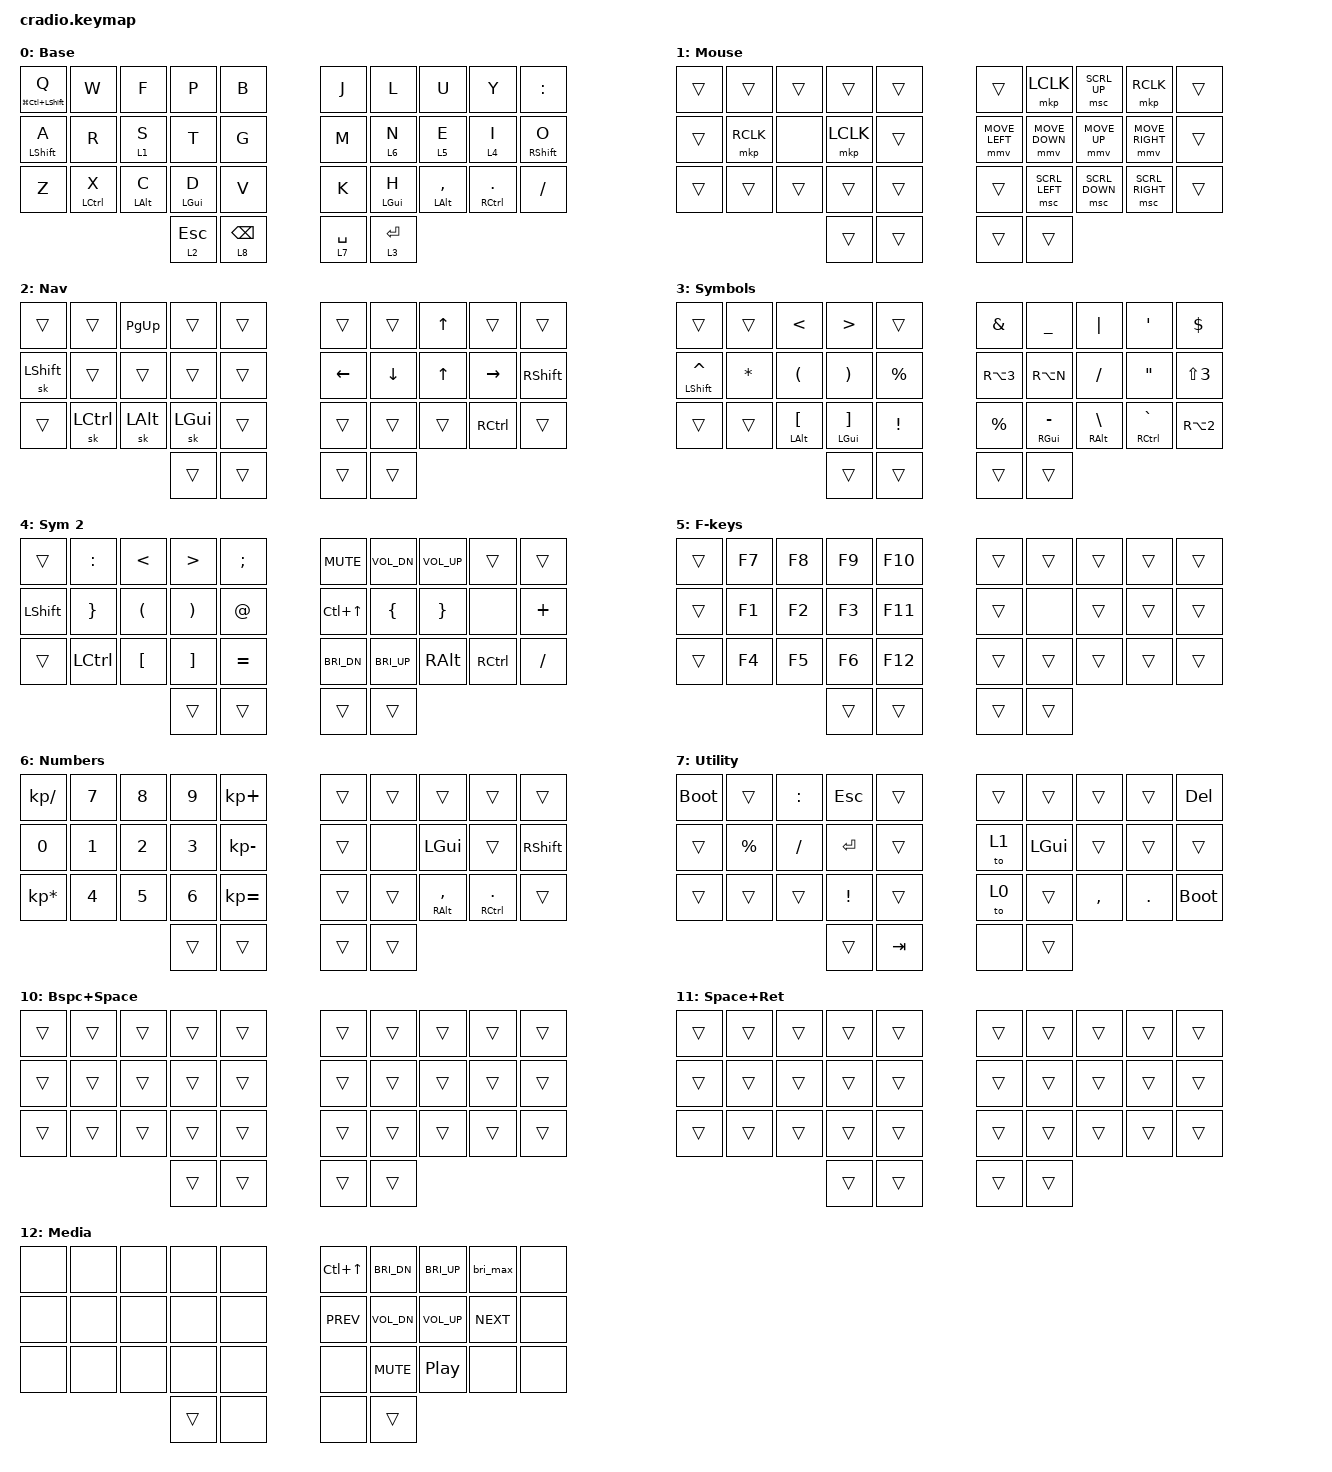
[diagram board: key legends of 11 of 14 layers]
// Copyright (c) 2022 The ZMK Contributors
// SPDX-License-Identifier: MIT

#include <behaviors.dtsi>
#include <dt-bindings/zmk/keys.h>
#include <dt-bindings/zmk/bt.h>
#include <dt-bindings/zmk/pointing.h>

// Indexes of the last layers below.
#define MEDIA 12
#define CLEANSHOT 13

// Tap a layer-tap key, then press and hold it within 175ms, and it repeats
// (eeee, or Backspace) instead of switching layer. Same window as mt.
&lt {
    quick-tap-ms = <175>;
};

/ {
    behaviors {
        // Balanced: a mod-tap becomes its modifier once another key goes down
        // and back up while it's held, however quick. Pressed alone it waits
        // 200ms, well above the slowest a/o taps hrm-tune measured (~140ms).
        // Keep a/o down until the capital letter is back up.
        mt: mod_tap {
            compatible = "zmk,behavior-hold-tap";
            label = "MOD_TAP";
            #binding-cells = <2>;
            flavor = "balanced";
            tapping-term-ms = <200>;
            quick-tap-ms = <175>;
            require-prior-idle-ms = <0>;
            bindings = <&kp>, <&kp>;
        };

    };

    macros {
        // Brightness up 20 times. The HID "brightness max" key (C_BRI_MAX)
        // is ignored by macOS; 20 steps tops out on macOS (16) and on Linux
        // (5% steps). Used on the Media layer.
        bri_max: brightness_max {
            compatible = "zmk,behavior-macro";
            display-name = "Bright max";
            #binding-cells = <0>;
            wait-ms = <10>;
            tap-ms = <10>;
            bindings = <&macro_tap
                &kp C_BRI_UP &kp C_BRI_UP &kp C_BRI_UP &kp C_BRI_UP &kp C_BRI_UP
                &kp C_BRI_UP &kp C_BRI_UP &kp C_BRI_UP &kp C_BRI_UP &kp C_BRI_UP
                &kp C_BRI_UP &kp C_BRI_UP &kp C_BRI_UP &kp C_BRI_UP &kp C_BRI_UP
                &kp C_BRI_UP &kp C_BRI_UP &kp C_BRI_UP &kp C_BRI_UP &kp C_BRI_UP>;
        };
    };

    conditional_layers {
        compatible = "zmk,conditional-layers";
        bspc_ret {
            if-layers = <8 3>;
            then-layer = <9>;
        };
        bspc_space {
            if-layers = <8 7>;
            then-layer = <10>;
        };
        space_ret {
            if-layers = <7 3>;
            then-layer = <11>;
        };
        esc_space {
            if-layers = <2 7>;
            then-layer = <CLEANSHOT>;
        };
        esc_ret {
            if-layers = <2 3>;
            then-layer = <MEDIA>;
        };
    };

    keymap {
        compatible = "zmk,keymap";

        // Layer 0: Default (Base Colemak-DH)
        default_layer {
            display-name = "Base";
            bindings = <
        //╭──────────┬──────────┬──────────┬──────────┬──────────╮   ╭──────────┬──────────┬──────────┬──────────┬──────────╮
        //│GUI+CTL+  │  W       │  F       │  P       │  B       │   │  J       │  L       │  U       │  Y       │  :       │
        //│  SFT+Q   │          │          │          │          │   │          │          │          │          │          │
            &mt LG(LC(LSHFT)) Q &kp W &kp F &kp P &kp B            &kp J &kp L &kp U &kp Y &kp COLON
        //├──────────┼──────────┼──────────┼──────────┼──────────┤   ├──────────┼──────────┼──────────┼──────────┼──────────┤
        //│ LSFT+A   │  R       │ LT1+S    │  T       │  G       │   │  M       │ LT6+N    │ LT5+E    │ LT4+I    │ RSFT+O   │
            &mt LSHFT A &kp R    &lt 1 S    &kp T      &kp G          &kp M      &lt 6 N    &lt 5 E    &lt 4 I    &mt RSHFT O
        //├──────────┼──────────┼──────────┼──────────┼──────────┤   ├──────────┼──────────┼──────────┼──────────┼──────────┤
        //│  Z       │ LCTL+X   │ LALT+C   │ LGUI+D   │  V       │   │  K       │ LGUI+H   │ LALT+,   │ RCTL+.   │  /       │
            &kp Z      &mt LCTRL X &mt LALT C &mt LGUI D &kp V       &kp K      &mt LGUI H &mt LALT COMMA &mt RCTRL DOT &kp FSLH
        //╰──────────┴──────────┴──────────┼──────────┼──────────┤   ├──────────┼──────────┼──────────┴──────────┴──────────╯
                                            &lt 2 ESC   &lt 8 BSPC    &lt 7 SPACE &lt 3 RET
        //                                 ╰──────────┴──────────╯   ╰──────────┴──────────╯
            >;
        };

        // Layer 1: Mouse controls (accessed via S key)
        layer_1 {
            display-name = "Mouse";
            bindings = <
        //╭──────────┬──────────┬──────────┬──────────┬──────────╮   ╭──────────┬──────────┬──────────┬──────────┬──────────╮
        //│          │          │          │          │          │   │          │ LCLK     │ SCR_UP   │ RCLK     │          │
            &trans     &trans     &trans     &trans     &trans         &trans     &mkp LCLK  &msc SCRL_UP &mkp RCLK &trans
        //├──────────┼──────────┼──────────┼──────────┼──────────┤   ├──────────┼──────────┼──────────┼──────────┼──────────┤
        //│          │ RCLK     │          │ LCLK     │          │   │ M_LEFT   │ M_DOWN   │ M_UP     │ M_RIGHT  │          │
            &trans     &mkp RCLK  &none      &mkp LCLK  &trans         &mmv MOVE_LEFT &mmv MOVE_DOWN &mmv MOVE_UP &mmv MOVE_RIGHT &trans
        //├──────────┼──────────┼──────────┼──────────┼──────────┤   ├──────────┼──────────┼──────────┼──────────┼──────────┤
        //│          │          │          │          │          │   │          │ SCR_LEFT │ SCR_DOWN │ SCR_RIGHT│          │
            &trans     &trans     &trans     &trans     &trans         &trans     &msc SCRL_LEFT &msc SCRL_DOWN &msc SCRL_RIGHT &trans
        //╰──────────┴──────────┴──────────┼──────────┼──────────┤   ├──────────┼──────────┼──────────┴──────────┴──────────╯
                                             &trans     &trans         &trans     &trans
        //                                 ╰──────────┴──────────╯   ╰──────────┴──────────╯
            >;
        };

        // Layer 2: Navigation and One-shot modifiers (accessed via ESC key)
        layer_2 {
            display-name = "Nav";
            bindings = <
        //╭──────────┬──────────┬──────────┬──────────┬──────────╮   ╭──────────┬──────────┬──────────┬──────────┬──────────╮
        //│          │          │ PAGE_UP  │          │          │   │          │          │ UP       │          │          │
            &trans     &trans     &kp PG_UP  &trans     &trans         &trans     &trans     &kp UP     &trans     &trans
        //├──────────┼──────────┼──────────┼──────────┼──────────┤   ├──────────┼──────────┼──────────┼──────────┼──────────┤
        //│ OS_LSFT  │          │          │          │          │   │ LEFT     │ DOWN     │ UP       │ RIGHT    │ RSFT     │
            &sk LSHFT  &trans     &trans     &trans     &trans         &kp LEFT   &kp DOWN   &kp UP     &kp RIGHT  &kp RSHFT
        //├──────────┼──────────┼──────────┼──────────┼──────────┤   ├──────────┼──────────┼──────────┼──────────┼──────────┤
        //│          │ OS_LCTL  │ OS_LALT  │ OS_LGUI  │          │   │          │          │          │ RCTL     │          │
            &trans     &sk LCTRL  &sk LALT   &sk LGUI   &trans         &trans     &trans     &trans     &kp RCTRL  &trans
        //╰──────────┴──────────┴──────────┼──────────┼──────────┤   ├──────────┼──────────┼──────────┴──────────┴──────────╯
                                             &trans     &trans         &trans     &trans
        //                                 ╰──────────┴──────────╯   ╰──────────┴──────────╯
            >;
        };

        // Layer 3: Symbols (accessed via RET key)
        layer_3 {
            display-name = "Symbols";
            bindings = <
        //╭──────────┬──────────┬──────────┬──────────┬──────────╮   ╭──────────┬──────────┬──────────┬──────────┬──────────╮
        //│          │          │ <        │ >        │          │   │ &        │ _        │ |        │ '        │ $        │
            &trans     &trans     &kp LT     &kp GT     &trans         &kp AMPS   &kp UNDER  &kp PIPE   &kp SQT    &kp DLLR
        //├──────────┼──────────┼──────────┼──────────┼──────────┤   ├──────────┼──────────┼──────────┼──────────┼──────────┤
        //│ LSFT+^   │ *        │ (        │ )        │ %        │   │ £        │ RALT+N   │ /        │ "        │ #        │
            &mt LSHFT CARET &kp ASTRK &kp LPAR &kp RPAR &kp PRCNT     &kp RA(N3) &kp RA(N)  &kp FSLH   &kp DQT    &kp LS(N3)
        //├──────────┼──────────┼──────────┼──────────┼──────────┤   ├──────────┼──────────┼──────────┼──────────┼──────────┤
        //│          │          │ LALT+[   │ LGUI+]   │ !        │   │ %        │ RGUI+-   │ RALT+\   │ RCTL+`   │ @        │
            &trans     &trans     &mt LALT LBKT &mt LGUI RBKT &kp EXCL  &kp PRCNT &mt RGUI MINUS &mt RALT BSLH &mt RCTRL GRAVE &kp RA(N2)
        //╰──────────┴──────────┴──────────┼──────────┼──────────┤   ├──────────┼──────────┼──────────┴──────────┴──────────╯
                                             &trans     &trans         &trans     &trans
        //                                 ╰──────────┴──────────╯   ╰──────────┴──────────╯
            >;
        };

        // Layer 4: More symbols and media (accessed via I key)
        layer_4 {
            display-name = "Sym 2";
            bindings = <
        //╭──────────┬──────────┬──────────┬──────────┬──────────╮   ╭──────────┬──────────┬──────────┬──────────┬──────────╮
        //│          │ :        │ <        │ >        │ ;        │   │ MUTE     │ VOL_DN   │ VOL_UP   │          │          │
            &trans     &kp COLON  &kp LT     &kp GT     &kp SEMI       &kp C_MUTE &kp C_VOL_DN &kp C_VOL_UP &trans   &trans
        //├──────────┼──────────┼──────────┼──────────┼──────────┤   ├──────────┼──────────┼──────────┼──────────┼──────────┤
        //│ LSHIFT   │ }        │ (        │ )        │ @        │   │ RCTL_UP  │ {        │ }        │          │ +        │
            &kp LSHFT  &kp RBRC   &kp LPAR   &kp RPAR   &kp AT         &kp LC(UP) &kp LBRC   &kp RBRC   &none      &kp PLUS
        //├──────────┼──────────┼──────────┼──────────┼──────────┤   ├──────────┼──────────┼──────────┼──────────┼──────────┤
        //│          │ LCTL     │ [        │ ]        │ =        │   │ BRI_DN   │ BRI_UP   │ RALT     │ RCTL     │ /        │
            &trans     &kp LCTRL  &kp LBKT   &kp RBKT   &kp EQUAL      &kp C_BRI_DN &kp C_BRI_UP &kp RALT &kp RCTRL &kp FSLH
        //╰──────────┴──────────┴──────────┼──────────┼──────────┤   ├──────────┼──────────┼──────────┴──────────┴──────────╯
                                             &trans     &trans         &trans     &trans
        //                                 ╰──────────┴──────────╯   ╰──────────┴──────────╯
            >;
        };

        // Layer 5: Function keys (accessed via E key)
        layer_5 {
            display-name = "F-keys";
            bindings = <
        //╭──────────┬──────────┬──────────┬──────────┬──────────╮   ╭──────────┬──────────┬──────────┬──────────┬──────────╮
        //│          │ F7       │ F8       │ F9       │ F10      │   │          │          │          │          │          │
            &trans     &kp F7     &kp F8     &kp F9     &kp F10        &trans     &trans     &trans     &trans     &trans
        //├──────────┼──────────┼──────────┼──────────┼──────────┤   ├──────────┼──────────┼──────────┼──────────┼──────────┤
        //│          │ F1       │ F2       │ F3       │ F11      │   │          │          │          │          │          │
            &trans     &kp F1     &kp F2     &kp F3     &kp F11        &trans     &none      &trans     &trans     &trans
        //├──────────┼──────────┼──────────┼──────────┼──────────┤   ├──────────┼──────────┼──────────┼──────────┼──────────┤
        //│          │ F4       │ F5       │ F6       │ F12      │   │          │          │          │          │          │
            &trans     &kp F4     &kp F5     &kp F6     &kp F12        &trans     &trans     &trans     &trans     &trans
        //╰──────────┴──────────┴──────────┼──────────┼──────────┤   ├──────────┼──────────┼──────────┴──────────┴──────────╯
                                             &trans     &trans         &trans     &trans
        //                                 ╰──────────┴──────────╯   ╰──────────┴──────────╯
            >;
        };

        // Layer 6: Number pad (accessed via N key)
        layer_6 {
            display-name = "Numbers";
            bindings = <
        //╭──────────┬──────────┬──────────┬──────────┬──────────╮   ╭──────────┬──────────┬──────────┬──────────┬──────────╮
        //│ /        │ 7        │ 8        │ 9        │ +        │   │          │          │          │          │          │
            &kp KP_SLASH &kp N7   &kp N8     &kp N9     &kp KP_PLUS    &trans     &trans     &trans     &trans     &trans
        //├──────────┼──────────┼──────────┼──────────┼──────────┤   ├──────────┼──────────┼──────────┼──────────┼──────────┤
        //│ 0        │ 1        │ 2        │ 3        │ -        │   │          │          │ LGUI     │          │ RSHIFT   │
            &kp N0     &kp N1     &kp N2     &kp N3     &kp KP_MINUS   &trans     &none      &kp LGUI   &trans     &kp RSHFT
        //├──────────┼──────────┼──────────┼──────────┼──────────┤   ├──────────┼──────────┼──────────┼──────────┼──────────┤
        //│ *        │ 4        │ 5        │ 6        │ =        │   │          │          │ RALT+,   │ RCTL+.   │          │
            &kp KP_MULTIPLY &kp N4 &kp N5    &kp N6      &kp KP_EQUAL  &trans     &trans     &mt RALT COMMA &mt RCTRL DOT &trans
        //╰──────────┴──────────┴──────────┼──────────┼──────────┤   ├──────────┼──────────┼──────────┴──────────┴──────────╯
                                             &trans     &trans         &trans     &trans
        //                                 ╰──────────┴──────────╯   ╰──────────┴──────────╯
            >;
        };

        // Layer 7: Utility (accessed via SPACE key)
        layer_7 {
            display-name = "Utility";
            bindings = <
        //╭──────────┬──────────┬──────────┬──────────┬──────────╮   ╭──────────┬──────────┬──────────┬──────────┬──────────╮
        //│BOOTLOADER│          │ :        │ ESC      │          │   │          │          │          │          │ DEL      │
            &bootloader &trans    &kp COLON  &kp ESC    &trans         &trans     &trans     &trans     &trans     &kp DEL
        //├──────────┼──────────┼──────────┼──────────┼──────────┤   ├──────────┼──────────┼──────────┼──────────┼──────────┤
        //│          │ %        │ /        │ ENTER    │          │   │ TO(1)    │ LGUI     │          │          │          │
            &trans     &kp PRCNT  &kp FSLH   &kp RET    &trans         &to 1      &kp LGUI   &trans     &trans     &trans
        //├──────────┼──────────┼──────────┼──────────┼──────────┤   ├──────────┼──────────┼──────────┼──────────┼──────────┤
        //│          │          │          │ !        │          │   │ TO(0)    │          │ ,        │ .        │BOOTLOADER│
            &trans     &trans     &trans     &kp EXCL   &trans         &to 0      &trans     &kp COMMA  &kp DOT    &bootloader
        //╰──────────┴──────────┴──────────┼──────────┼──────────┤   ├──────────┼──────────┼──────────┴──────────┴──────────╯
                                             &trans     &kp TAB        &none      &trans
        //                                 ╰──────────┴──────────╯   ╰──────────┴──────────╯
            >;
        };

        // Layer 8: MEH combinations (accessed via BSPC key)
        layer_8 {
            display-name = "MEH";
            bindings = <
        //╭──────────┬──────────┬──────────┬──────────┬──────────╮   ╭──────────┬──────────┬──────────┬──────────┬──────────╮
        //│MEH+Q     │MEH+W     │MEH+F     │MEH+P     │MEH+B     │   │S-G+[     │MEH+L     │MEH+U     │S-G+]     │MEH+;     │
            &kp LC(LA(LS(Q))) &kp LC(LA(LS(W))) &kp LC(LA(LS(F))) &kp LC(LA(LS(P))) &kp LC(LA(LS(B)))   &kp LS(LG(LBKT)) &kp LC(LA(LS(L))) &kp LC(LA(LS(U))) &kp LS(LG(RBKT)) &kp LC(LA(LS(SEMI)))
        //├──────────┼──────────┼──────────┼──────────┼──────────┤   ├──────────┼──────────┼──────────┼──────────┼──────────┤
        //│MEH+A     │MEH+1     │MEH+2     │MEH+3     │MEH+G     │   │MEH+M     │MEH+N     │MEH+E     │MEH+I     │MEH+O     │
            &kp LC(LA(LS(A))) &kp LC(LA(LS(N1))) &kp LC(LA(LS(N2))) &kp LC(LA(LS(N3))) &kp LC(LA(LS(G)))   &kp LC(LA(LS(M))) &kp LC(LA(LS(N))) &kp LC(LA(LS(E))) &kp LC(LA(LS(I))) &kp LC(LA(LS(O)))
        //├──────────┼──────────┼──────────┼──────────┼──────────┤   ├──────────┼──────────┼──────────┼──────────┼──────────┤
        //│MEH+Z     │MEH+4     │MEH+5     │MEH+6     │MEH+V     │   │MEH+K     │MEH+H     │MEH+,     │MEH+.     │MEH+/     │
            &kp LC(LA(LS(Z))) &kp LC(LA(LS(N4))) &kp LC(LA(LS(N5))) &kp LC(LA(LS(N6)))      &kp LC(LA(LS(V)))   &kp LC(LA(LS(K))) &kp LC(LA(LS(H))) &kp LC(LA(LS(COMMA))) &kp LC(LA(LS(DOT))) &kp LC(LA(LS(FSLH)))
        //╰──────────┴──────────┴──────────┼──────────┼──────────┤   ├──────────┼──────────┼──────────┴──────────┴──────────╯
                                             &trans     &none          &kp LC(LA(LS(SPACE))) &trans
        //                                 ╰──────────┴──────────╯   ╰──────────┴──────────╯
            >;
        };

        // Layer 9: HYPER combinations (hold BSPC + RET, either one first)
        // Same positions as the MEH layer plus GUI: BSPC+T goes to workspace 3,
        // BSPC+RET+T takes the window there. Other keys fall through to MEH.
        // One thumb per hand; the right thumb is on RET, so HYPER+V stands in
        // for HYPER+SPACE (both move the window to the other monitor).
        // BSPC+MNEI focuses a window, BSPC+RET+MNEI moves it that way.
        // BSPC+J/Y switch tabs in an app, BSPC+RET+J/Y the windows in a group.
        // F and L take Omarchy's SUPER+F (full screen) and SUPER+L (layout),
        // which give way to ⌘F and ⌘L in apps.
        layer_9 {
            display-name = "HYPER";
            bindings = <
        //╭──────────┬──────────┬──────────┬──────────┬──────────╮   ╭──────────┬──────────┬──────────┬──────────┬──────────╮
        //│          │          │HYPER+F   │HYPER+P   │HYPER+B   │   │HYPER+J   │HYPER+L   │HYPER+U   │HYPER+Y   │          │
            &trans     &trans     &kp LG(LC(LA(LS(F)))) &kp LG(LC(LA(LS(P)))) &kp LG(LC(LA(LS(B))))   &kp LG(LC(LA(LS(J)))) &kp LG(LC(LA(LS(L)))) &kp LG(LC(LA(LS(U)))) &kp LG(LC(LA(LS(Y)))) &trans
        //├──────────┼──────────┼──────────┼──────────┼──────────┤   ├──────────┼──────────┼──────────┼──────────┼──────────┤
        //│          │HYPER+1   │HYPER+2   │HYPER+3   │          │   │HYPER+M   │HYPER+N   │HYPER+E   │HYPER+I   │          │
            &trans     &kp LG(LC(LA(LS(N1)))) &kp LG(LC(LA(LS(N2)))) &kp LG(LC(LA(LS(N3)))) &trans   &kp LG(LC(LA(LS(M)))) &kp LG(LC(LA(LS(N)))) &kp LG(LC(LA(LS(E)))) &kp LG(LC(LA(LS(I)))) &trans
        //├──────────┼──────────┼──────────┼──────────┼──────────┤   ├──────────┼──────────┼──────────┼──────────┼──────────┤
        //│          │HYPER+4   │HYPER+5   │HYPER+6   │HYPER+V   │   │          │          │          │          │          │
            &trans     &kp LG(LC(LA(LS(N4)))) &kp LG(LC(LA(LS(N5)))) &kp LG(LC(LA(LS(N6)))) &kp LG(LC(LA(LS(V))))   &trans     &trans     &trans     &trans     &trans
        //╰──────────┴──────────┴──────────┼──────────┼──────────┤   ├──────────┼──────────┼──────────┴──────────┴──────────╯
                                             &trans     &trans         &trans     &trans
        //                                 ╰──────────┴──────────╯   ╰──────────┴──────────╯
            >;
        };

        // Layer 10: Conditional BSPC + SPACE (layers 8 + 7)
        layer_10 {
            display-name = "Bspc+Space";
            bindings = <
        //╭──────────┬──────────┬──────────┬──────────┬──────────╮   ╭──────────┬──────────┬──────────┬──────────┬──────────╮
            &trans     &trans     &trans     &trans     &trans         &trans     &trans     &trans     &trans     &trans
        //├──────────┼──────────┼──────────┼──────────┼──────────┤   ├──────────┼──────────┼──────────┼──────────┼──────────┤
            &trans     &trans     &trans     &trans     &trans         &trans     &trans     &trans     &trans     &trans
        //├──────────┼──────────┼──────────┼──────────┼──────────┤   ├──────────┼──────────┼──────────┼──────────┼──────────┤
            &trans     &trans     &trans     &trans     &trans         &trans     &trans     &trans     &trans     &trans
        //╰──────────┴──────────┴──────────┼──────────┼──────────┤   ├──────────┼──────────┼──────────┴──────────┴──────────╯
                                             &trans     &trans         &trans     &trans
        //                                 ╰──────────┴──────────╯   ╰──────────┴──────────╯
            >;
        };

        // Layer 11: Conditional SPACE + ENTER (layers 7 + 3)
        layer_11 {
            display-name = "Space+Ret";
            bindings = <
        //╭──────────┬──────────┬──────────┬──────────┬──────────╮   ╭──────────┬──────────┬──────────┬──────────┬──────────╮
            &trans     &trans     &trans     &trans     &trans         &trans     &trans     &trans     &trans     &trans
        //├──────────┼──────────┼──────────┼──────────┼──────────┤   ├──────────┼──────────┼──────────┼──────────┼──────────┤
            &trans     &trans     &trans     &trans     &trans         &trans     &trans     &trans     &trans     &trans
        //├──────────┼──────────┼──────────┼──────────┼──────────┤   ├──────────┼──────────┼──────────┼──────────┼──────────┤
            &trans     &trans     &trans     &trans     &trans         &trans     &trans     &trans     &trans     &trans
        //╰──────────┴──────────┴──────────┼──────────┼──────────┤   ├──────────┼──────────┼──────────┴──────────┴──────────╯
                                             &trans     &trans         &trans     &trans
        //                                 ╰──────────┴──────────╯   ╰──────────┴──────────╯
            >;
        };

        // Layer 12: Media (hold ESC + RET, either one first)
        // A Mac's top row. M N E I are left/down/up/right as everywhere else:
        // previous track, volume down, volume up, next track. Brightness sits
        // above the volume keys (Y: all the way up), mute and play/pause below
        // them, and J is Mission Control. Everything else is blocked, so
        // nothing falls through to the Nav or Symbols layer the thumbs hold.
        media_layer {
            display-name = "Media";
            bindings = <
        //╭──────────┬──────────┬──────────┬──────────┬──────────╮   ╭──────────┬──────────┬──────────┬──────────┬──────────╮
        //│          │          │          │          │          │   │ MISSION  │ BRI_DN   │ BRI_UP   │ BRI_MAX  │          │
            &none      &none      &none      &none      &none          &kp LC(UP) &kp C_BRI_DN &kp C_BRI_UP &bri_max &none
        //├──────────┼──────────┼──────────┼──────────┼──────────┤   ├──────────┼──────────┼──────────┼──────────┼──────────┤
        //│          │          │          │          │          │   │ PREV     │ VOL_DN   │ VOL_UP   │ NEXT     │          │
            &none      &none      &none      &none      &none          &kp C_PREV &kp C_VOL_DN &kp C_VOL_UP &kp C_NEXT &none
        //├──────────┼──────────┼──────────┼──────────┼──────────┤   ├──────────┼──────────┼──────────┼──────────┼──────────┤
        //│          │          │          │          │          │   │          │ MUTE     │ PLAY     │          │          │
            &none      &none      &none      &none      &none          &none      &kp C_MUTE &kp C_PP   &none      &none
        //╰──────────┴──────────┴──────────┼──────────┼──────────┤   ├──────────┼──────────┼──────────┴──────────┴──────────╯
        //                                 │ (held)   │          │   │          │ (held)   │
                                             &trans     &none          &none      &trans
        //                                 ╰──────────┴──────────╯   ╰──────────┴──────────╯
            >;
        };

        // Layer 13: CleanShot (hold ESC + SPACE, either one first)
        // Every letter sends Ctrl+Opt+Cmd + that letter, which nothing else
        // uses (MEH and HYPER both include Shift), so any letter can be given
        // any CleanShot action in its Shortcuts settings. Suggested:
        // A area, P previous area, F fullscreen, W window, S scrolling,
        // T text (OCR), R record screen, D desktop icons, H history.
        // Everything else is blocked so nothing falls through to layer 7.
        cleanshot_layer {
            display-name = "Screenshots";
            bindings = <
        //╭──────────┬──────────┬──────────┬──────────┬──────────╮   ╭──────────┬──────────┬──────────┬──────────┬──────────╮
        //│ ⌃⌥⌘ Q    │ ⌃⌥⌘ W    │ ⌃⌥⌘ F    │ ⌃⌥⌘ P    │ ⌃⌥⌘ B    │   │ ⌃⌥⌘ J    │ ⌃⌥⌘ L    │ ⌃⌥⌘ U    │ ⌃⌥⌘ Y    │          │
            &kp LC(LA(LG(Q))) &kp LC(LA(LG(W))) &kp LC(LA(LG(F))) &kp LC(LA(LG(P))) &kp LC(LA(LG(B)))   &kp LC(LA(LG(J))) &kp LC(LA(LG(L))) &kp LC(LA(LG(U))) &kp LC(LA(LG(Y))) &none
        //├──────────┼──────────┼──────────┼──────────┼──────────┤   ├──────────┼──────────┼──────────┼──────────┼──────────┤
        //│ ⌃⌥⌘ A    │ ⌃⌥⌘ R    │ ⌃⌥⌘ S    │ ⌃⌥⌘ T    │ ⌃⌥⌘ G    │   │ ⌃⌥⌘ M    │ ⌃⌥⌘ N    │ ⌃⌥⌘ E    │ ⌃⌥⌘ I    │ ⌃⌥⌘ O    │
            &kp LC(LA(LG(A))) &kp LC(LA(LG(R))) &kp LC(LA(LG(S))) &kp LC(LA(LG(T))) &kp LC(LA(LG(G)))   &kp LC(LA(LG(M))) &kp LC(LA(LG(N))) &kp LC(LA(LG(E))) &kp LC(LA(LG(I))) &kp LC(LA(LG(O)))
        //├──────────┼──────────┼──────────┼──────────┼──────────┤   ├──────────┼──────────┼──────────┼──────────┼──────────┤
        //│ ⌃⌥⌘ Z    │ ⌃⌥⌘ X    │ ⌃⌥⌘ C    │ ⌃⌥⌘ D    │ ⌃⌥⌘ V    │   │ ⌃⌥⌘ K    │ ⌃⌥⌘ H    │          │          │          │
            &kp LC(LA(LG(Z))) &kp LC(LA(LG(X))) &kp LC(LA(LG(C))) &kp LC(LA(LG(D))) &kp LC(LA(LG(V)))   &kp LC(LA(LG(K))) &kp LC(LA(LG(H))) &none &none &none
        //╰──────────┴──────────┴──────────┼──────────┼──────────┤   ├──────────┼──────────┼──────────┴──────────┴──────────╯
        //                                 │ (held)   │          │   │ (held)   │          │
                                             &trans     &none          &trans     &none
        //                                 ╰──────────┴──────────╯   ╰──────────┴──────────╯
            >;
        };
    };
};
